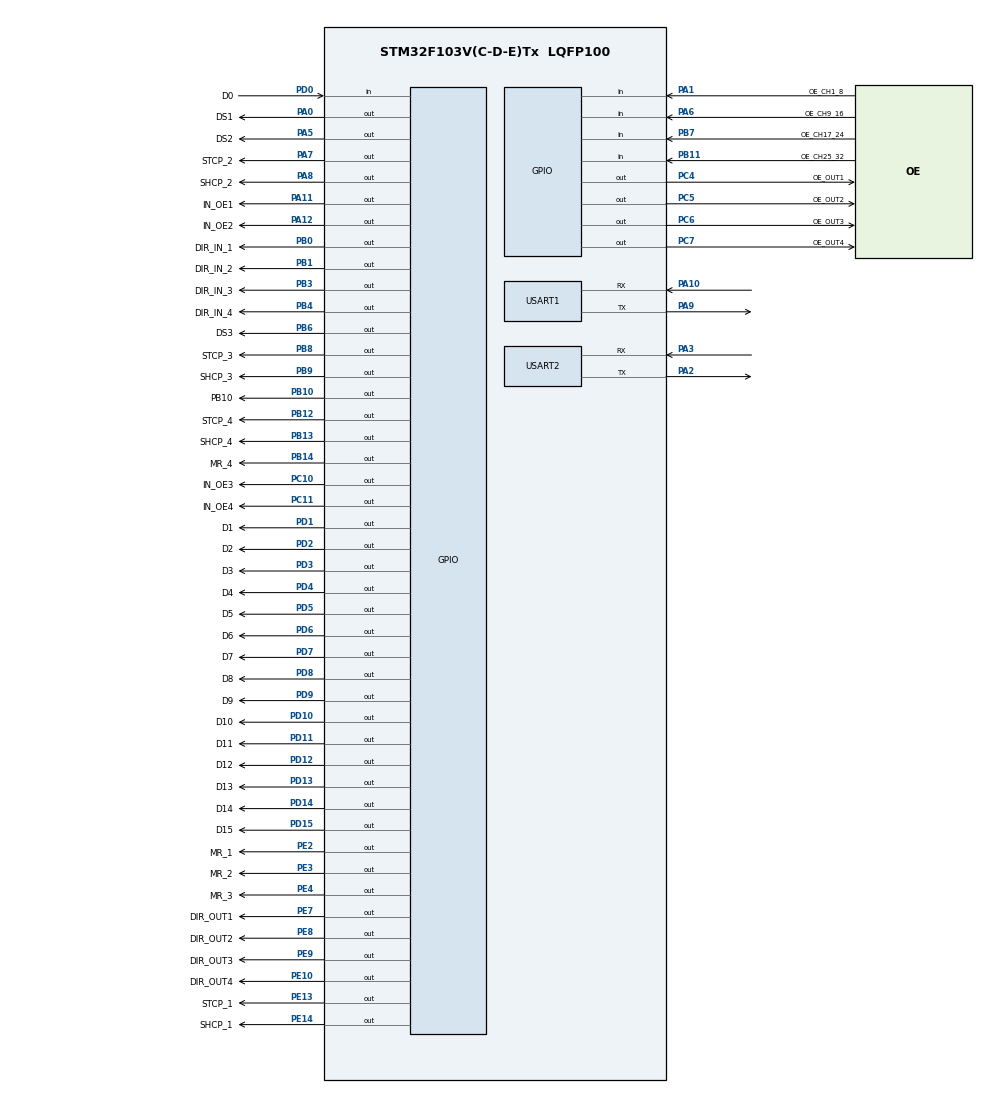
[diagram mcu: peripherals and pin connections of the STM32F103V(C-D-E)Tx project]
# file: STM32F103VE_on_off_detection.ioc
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Dma.Request0=USART1_RX
Dma.Request1=USART1_TX
Dma.Request2=USART2_RX
Dma.Request3=USART2_TX
Dma.USART1_RX.0.Direction=DMA_PERIPH_TO_MEMORY
Dma.USART1_RX.0.Instance=DMA1_Channel5
Dma.USART1_RX.0.MemDataAlignment=DMA_MDATAALIGN_BYTE
Dma.USART1_RX.0.MemInc=DMA_MINC_ENABLE
Dma.USART1_RX.0.Mode=DMA_NORMAL
Dma.USART1_RX.0.PeriphDataAlignment=DMA_PDATAALIGN_BYTE
Dma.USART1_RX.0.PeriphInc=DMA_PINC_DISABLE
Dma.USART1_RX.0.Priority=DMA_PRIORITY_LOW
Dma.USART1_TX.1.Direction=DMA_MEMORY_TO_PERIPH
Dma.USART1_TX.1.Instance=DMA1_Channel4
Dma.USART1_TX.1.MemDataAlignment=DMA_MDATAALIGN_BYTE
Dma.USART1_TX.1.MemInc=DMA_MINC_ENABLE
Dma.USART1_TX.1.Mode=DMA_NORMAL
Dma.USART1_TX.1.PeriphDataAlignment=DMA_PDATAALIGN_BYTE
Dma.USART1_TX.1.PeriphInc=DMA_PINC_DISABLE
Dma.USART1_TX.1.Priority=DMA_PRIORITY_LOW
Dma.USART2_RX.2.Direction=DMA_PERIPH_TO_MEMORY
Dma.USART2_RX.2.Instance=DMA1_Channel6
Dma.USART2_RX.2.MemDataAlignment=DMA_MDATAALIGN_BYTE
Dma.USART2_RX.2.MemInc=DMA_MINC_ENABLE
Dma.USART2_RX.2.Mode=DMA_NORMAL
Dma.USART2_RX.2.PeriphDataAlignment=DMA_PDATAALIGN_BYTE
Dma.USART2_RX.2.PeriphInc=DMA_PINC_DISABLE
Dma.USART2_RX.2.Priority=DMA_PRIORITY_LOW
Dma.USART2_TX.3.Direction=DMA_MEMORY_TO_PERIPH
Dma.USART2_TX.3.Instance=DMA1_Channel7
Dma.USART2_TX.3.MemDataAlignment=DMA_MDATAALIGN_BYTE
Dma.USART2_TX.3.MemInc=DMA_MINC_ENABLE
Dma.USART2_TX.3.Mode=DMA_NORMAL
Dma.USART2_TX.3.PeriphDataAlignment=DMA_PDATAALIGN_BYTE
Dma.USART2_TX.3.PeriphInc=DMA_PINC_DISABLE
Dma.USART2_TX.3.Priority=DMA_PRIORITY_LOW
Mcu.Family=STM32F1
Mcu.Name=STM32F103V(C-D-E)Tx
Mcu.Package=LQFP100
NVIC.DMA1_Channel4_IRQn=true\:0\:0\:false\:false\:true\:false\:true\:true
NVIC.DMA1_Channel5_IRQn=true\:0\:0\:false\:false\:true\:false\:true\:true
NVIC.DMA1_Channel6_IRQn=true\:0\:0\:false\:false\:true\:false\:true\:true
NVIC.DMA1_Channel7_IRQn=true\:0\:0\:false\:false\:true\:false\:true\:true
NVIC.PriorityGroup=NVIC_PRIORITYGROUP_4
NVIC.USART1_IRQn=true\:0\:0\:false\:false\:true\:true\:true\:true
NVIC.USART2_IRQn=true\:0\:0\:false\:false\:true\:true\:true\:true
PA0-WKUP.GPIO_Label=DS1
PA0-WKUP.Signal=GPIO_Output
PA1.GPIO_Label=OE_CH1_8
PA1.Signal=GPIO_Input
PA10.Mode=Asynchronous
PA10.Signal=USART1_RX
PA11.GPIO_Label=IN_OE1
PA11.Signal=GPIO_Output
PA12.GPIO_Label=IN_OE2
PA12.Signal=GPIO_Output
PA13.Mode=Serial_Wire
PA13.Signal=SYS_JTMS-SWDIO
PA14.Mode=Serial_Wire
PA14.Signal=SYS_JTCK-SWCLK
PA2.Mode=Asynchronous
PA2.Signal=USART2_TX
PA3.Mode=Asynchronous
PA3.Signal=USART2_RX
PA5.GPIO_Label=DS2
PA5.Signal=GPIO_Output
PA6.GPIO_Label=OE_CH9_16
PA6.Signal=GPIO_Input
PA7.GPIO_Label=STCP_2
PA7.Signal=GPIO_Output
PA8.GPIO_Label=SHCP_2
PA8.Signal=GPIO_Output
PA9.Mode=Asynchronous
PA9.Signal=USART1_TX
PB0.GPIO_Label=DIR_IN_1
PB0.Signal=GPIO_Output
PB1.GPIO_Label=DIR_IN_2
PB1.Signal=GPIO_Output
PB10.GPIO_Label=PB10
PB10.Signal=GPIO_Output
PB11.GPIO_Label=OE_CH25_32
PB11.Signal=GPIO_Input
PB12.GPIO_Label=STCP_4
PB12.Signal=GPIO_Output
PB13.GPIO_Label=SHCP_4
PB13.Signal=GPIO_Output
PB14.GPIO_Label=MR_4
PB14.Signal=GPIO_Output
PB3.GPIO_Label=DIR_IN_3
PB3.Signal=GPIO_Output
PB4.GPIO_Label=DIR_IN_4
PB4.Signal=GPIO_Output
PB6.GPIO_Label=DS3
PB6.Signal=GPIO_Output
PB7.GPIO_Label=OE_CH17_24
PB7.Signal=GPIO_Input
PB8.GPIO_Label=STCP_3
PB8.Signal=GPIO_Output
PB9.GPIO_Label=SHCP_3
PB9.Signal=GPIO_Output
PC10.GPIO_Label=IN_OE3
PC10.Signal=GPIO_Output
PC11.GPIO_Label=IN_OE4
PC11.Signal=GPIO_Output
PC4.GPIO_Label=OE_OUT1
PC4.Signal=GPIO_Output
PC5.GPIO_Label=OE_OUT2
PC5.Signal=GPIO_Output
PC6.GPIO_Label=OE_OUT3
PC6.Signal=GPIO_Output
PC7.GPIO_Label=OE_OUT4
PC7.Signal=GPIO_Output
PD0.GPIO_Label=D0
PD0.Signal=GPIO_Input
PD1.GPIO_Label=D1
PD1.Signal=GPIO_Output
PD10.GPIO_Label=D10
PD10.Signal=GPIO_Output
PD11.GPIO_Label=D11
PD11.Signal=GPIO_Output
PD12.GPIO_Label=D12
PD12.Signal=GPIO_Output
PD13.GPIO_Label=D13
PD13.Signal=GPIO_Output
PD14.GPIO_Label=D14
PD14.Signal=GPIO_Output
PD15.GPIO_Label=D15
PD15.Signal=GPIO_Output
PD2.GPIO_Label=D2
PD2.Signal=GPIO_Output
PD3.GPIO_Label=D3
PD3.Signal=GPIO_Output
PD4.GPIO_Label=D4
PD4.Signal=GPIO_Output
PD5.GPIO_Label=D5
PD5.Signal=GPIO_Output
PD6.GPIO_Label=D6
PD6.Signal=GPIO_Output
PD7.GPIO_Label=D7
PD7.Signal=GPIO_Output
PD8.GPIO_Label=D8
PD8.Signal=GPIO_Output
PD9.GPIO_Label=D9
PD9.Signal=GPIO_Output
PE10.GPIO_Label=DIR_OUT4
PE10.Signal=GPIO_Output
PE13.GPIO_Label=STCP_1
PE13.Signal=GPIO_Output
PE14.GPIO_Label=SHCP_1
PE14.Signal=GPIO_Output
PE2.GPIO_Label=MR_1
PE2.Signal=GPIO_Output
PE3.GPIO_Label=MR_2
PE3.Signal=GPIO_Output
PE4.GPIO_Label=MR_3
PE4.Signal=GPIO_Output
PE7.GPIO_Label=DIR_OUT1
PE7.Signal=GPIO_Output
PE8.GPIO_Label=DIR_OUT2
PE8.Signal=GPIO_Output
PE9.GPIO_Label=DIR_OUT3
PE9.Signal=GPIO_Output
ProjectManager.HeapSize=0x200
ProjectManager.StackSize=0x400
ProjectManager.TargetToolchain=Makefile
RCC.APB1Freq_Value=8000000
RCC.APB2Freq_Value=8000000
USART1.VirtualMode=VM_ASYNC
USART2.VirtualMode=VM_ASYNC
board=custom

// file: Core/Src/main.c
/* USER CODE BEGIN Header */
/**
  ******************************************************************************
  * @file           : main.c
  * @brief          : Main program body
  ******************************************************************************
  * @attention
  *
  * Copyright (c) 2024 STMicroelectronics.
  * All rights reserved.
  *
  * This software is licensed under terms that can be found in the LICENSE file
  * in the root directory of this software component.
  * If no LICENSE file comes with this software, it is provided AS-IS.
  *
  ******************************************************************************
  */
/* USER CODE END Header */
#include "main.h"
#include "dma.h"
#include "usart.h"
#include "gpio.h"

void SystemClock_Config(void);

int main(void)
{

  /* MCU Configuration--------------------------------------------------------*/

  /* Reset of all peripherals, Initializes the Flash interface and the Systick. */
  HAL_Init();

  /* Configure the system clock */
  SystemClock_Config();

  /* Initialize all configured peripherals */
  MX_GPIO_Init();
  MX_DMA_Init();
  MX_USART1_UART_Init();
  MX_USART2_UART_Init();

  /* Infinite loop */
  /* USER CODE BEGIN WHILE */
  while (1)
  {
    printf("Hello World!\r\n");
    HAL_Delay(1000);
    /* USER CODE END WHILE */

  }
}

void SystemClock_Config(void)
{
  RCC_OscInitTypeDef RCC_OscInitStruct = {0};
  RCC_ClkInitTypeDef RCC_ClkInitStruct = {0};

  /** Initializes the RCC Oscillators according to the specified parameters
  * in the RCC_OscInitTypeDef structure.
  */
  RCC_OscInitStruct.OscillatorType = RCC_OSCILLATORTYPE_HSI;
  RCC_OscInitStruct.HSIState = RCC_HSI_ON;
  RCC_OscInitStruct.HSICalibrationValue = RCC_HSICALIBRATION_DEFAULT;
  RCC_OscInitStruct.PLL.PLLState = RCC_PLL_NONE;
  if (HAL_RCC_OscConfig(&RCC_OscInitStruct) != HAL_OK)
  {
    Error_Handler();
  }

  /** Initializes the CPU, AHB and APB buses clocks
  */
  RCC_ClkInitStruct.ClockType = RCC_CLOCKTYPE_HCLK|RCC_CLOCKTYPE_SYSCLK
                              |RCC_CLOCKTYPE_PCLK1|RCC_CLOCKTYPE_PCLK2;
  RCC_ClkInitStruct.SYSCLKSource = RCC_SYSCLKSOURCE_HSI;
  RCC_ClkInitStruct.AHBCLKDivider = RCC_SYSCLK_DIV1;
  RCC_ClkInitStruct.APB1CLKDivider = RCC_HCLK_DIV1;
  RCC_ClkInitStruct.APB2CLKDivider = RCC_HCLK_DIV1;

  if (HAL_RCC_ClockConfig(&RCC_ClkInitStruct, FLASH_LATENCY_0) != HAL_OK)
  {
    Error_Handler();
  }
}

/* USER CODE BEGIN 4 */
int _write(int fd, char *ptr, int len)
{
  HAL_UART_Transmit(&huart2, (uint8_t*)ptr, len, 0xFFFF);
  return len;
}
/* USER CODE END 4 */

void Error_Handler(void)
{
  __disable_irq();
  while (1)
  {
  }
}
